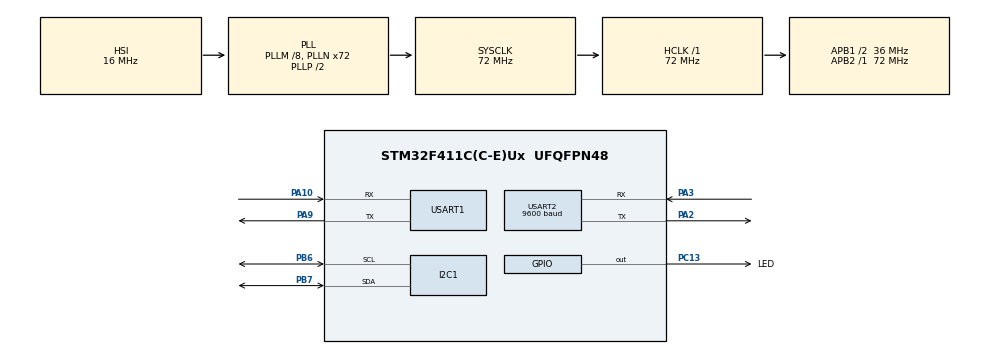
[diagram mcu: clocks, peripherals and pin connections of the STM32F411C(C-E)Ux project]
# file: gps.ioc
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Mcu.Family=STM32F4
Mcu.Name=STM32F411C(C-E)Ux
Mcu.Package=UFQFPN48
NVIC.PriorityGroup=NVIC_PRIORITYGROUP_4
NVIC.USART2_IRQn=true\:0\:0\:false\:false\:true\:true\:true
PA10.Mode=Asynchronous
PA10.Signal=USART1_RX
PA13.Mode=Serial_Wire
PA13.Signal=SYS_JTMS-SWDIO
PA14.Mode=Serial_Wire
PA14.Signal=SYS_JTCK-SWCLK
PA2.Mode=Asynchronous
PA2.Signal=USART2_TX
PA3.Mode=Asynchronous
PA3.Signal=USART2_RX
PA9.Mode=Asynchronous
PA9.Signal=USART1_TX
PB6.Mode=I2C
PB6.Signal=I2C1_SCL
PB7.Mode=I2C
PB7.Signal=I2C1_SDA
PC13-ANTI_TAMP.GPIO_Label=LED
PC13-ANTI_TAMP.Signal=GPIO_Output
PH0\ -\ OSC_IN.Mode=HSE-External-Oscillator
PH0\ -\ OSC_IN.Signal=RCC_OSC_IN
PH1\ -\ OSC_OUT.Mode=HSE-External-Oscillator
PH1\ -\ OSC_OUT.Signal=RCC_OSC_OUT
ProjectManager.HeapSize=0x200
ProjectManager.StackSize=0x400
ProjectManager.TargetToolchain=STM32CubeIDE
RCC.48MHZClocksFreq_Value=36000000
RCC.AHBFreq_Value=72000000
RCC.APB1CLKDivider=RCC_HCLK_DIV2
RCC.APB1Freq_Value=36000000
RCC.APB1TimFreq_Value=72000000
RCC.APB2Freq_Value=72000000
RCC.APB2TimFreq_Value=72000000
RCC.CortexFreq_Value=72000000
RCC.HCLKFreq_Value=72000000
RCC.HSE_VALUE=25000000
RCC.HSI_VALUE=16000000
RCC.LSE_VALUE=32768
RCC.PLLM=8
RCC.PLLN=72
RCC.SYSCLKFreq_VALUE=72000000
RCC.SYSCLKSource=RCC_SYSCLKSOURCE_PLLCLK
RCC.VCOOutputFreq_Value=144000000
USART1.VirtualMode=VM_ASYNC
USART2.BaudRate=9600
USART2.VirtualMode=VM_ASYNC
board=custom

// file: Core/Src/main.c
/* USER CODE BEGIN Header */
/**
  ******************************************************************************
  * @file           : main.c
  * @brief          : Main program body
  ******************************************************************************
  * @attention
  *
  * Copyright (c) 2021 STMicroelectronics.
  * All rights reserved.
  *
  * This software is licensed under terms that can be found in the LICENSE file
  * in the root directory of this software component.
  * If no LICENSE file comes with this software, it is provided AS-IS.
  *
  ******************************************************************************
  */
/* USER CODE END Header */
#include "main.h"

/* USER CODE BEGIN Includes */
#include <stdio.h>
#include "gps.h"
/* USER CODE END Includes */

I2C_HandleTypeDef hi2c1;

UART_HandleTypeDef huart1;
UART_HandleTypeDef huart2;

/* USER CODE BEGIN PV */
uint8_t Message[64];
uint8_t MessageLength;
/* USER CODE END PV */

void SystemClock_Config(void);
static void MX_GPIO_Init(void);
static void MX_USART1_UART_Init(void);
static void MX_I2C1_Init(void);
static void MX_USART2_UART_Init(void);

int main(void)
{

  /* MCU Configuration--------------------------------------------------------*/

  /* Reset of all peripherals, Initializes the Flash interface and the Systick. */
  HAL_Init();

  /* Configure the system clock */
  SystemClock_Config();

  /* Initialize all configured peripherals */
  MX_GPIO_Init();
  MX_USART1_UART_Init();
  MX_I2C1_Init();
  MX_USART2_UART_Init();
  /* USER CODE BEGIN 2 */
  NEO6_Init(&GpsState, &huart2);

  uint32_t Timer = HAL_GetTick();
  /* USER CODE END 2 */

  /* Infinite loop */
  while (1)
  {
	  NEO6_Task(&GpsState);

	  	  if((HAL_GetTick() - Timer) > 1000)
	  	  {
	  		  MessageLength = sprintf((char*)Message, " \n\r  "); // Clear terminal and home cursor
	  		  HAL_UART_Transmit(&huart1, Message, MessageLength, 1000);

	  		  if(NEO6_IsFix(&GpsState) && NEO6_FixMode(&GpsState))
	  		  {
	  			  MessageLength = sprintf((char*)Message, "UTC Time: %02d:%02d:%02d\n\r", GpsState.Hour, GpsState.Minute, GpsState.Second);
	  			  HAL_UART_Transmit(&huart1, Message, MessageLength, 1000);

	  			  MessageLength = sprintf((char*)Message, "Date: %02d.%02d.20%02d\n\r", GpsState.Day, GpsState.Month, GpsState.Year);
	  			  HAL_UART_Transmit(&huart1, Message, MessageLength, 1000);

	  			  MessageLength = sprintf((char*)Message, "Latitude: %.2f %c\n\r", GpsState.Latitude, GpsState.LatitudeDirection);
	  			  HAL_UART_Transmit(&huart1, Message, MessageLength, 1000);

	  			  MessageLength = sprintf((char*)Message, "Longitude: %.2f %c\n\r", GpsState.Longitude, GpsState.LongitudeDirection);
	  			  HAL_UART_Transmit(&huart1, Message, MessageLength, 1000);

	  			  MessageLength = sprintf((char*)Message, "Altitude: %.2f m above sea level\n\r", GpsState.Altitude);
	  			  HAL_UART_Transmit(&huart1, Message, MessageLength, 1000);

	  			  /*MessageLength = sprintf((char*)Message, "PositionValid: ");
	  			  HAL_UART_Transmit(&huart1, Message, MessageLength, 1000);
	  			  //MessageLength = sprintf((char*)Message, GpsState.PositionValid);
	  				  			  HAL_UART_Transmit(&huart1, GpsState.PositionValid, 1, 1000);
	  				  			MessageLength = sprintf((char*)Message, "\n\r ");
	  				  				  			  HAL_UART_Transmit(&huart1, Message, MessageLength, 1000);*/

	  			  MessageLength = sprintf((char*)Message, "Speed: %.2f knots, %f km/h\n\r", GpsState.SpeedKnots, GpsState.SpeedKilometers);
	  			  HAL_UART_Transmit(&huart1, Message, MessageLength, 1000);
	  			  MessageLength = sprintf((char*)Message, "Course: %.2f degrees\n\r", GpsState.Course);
	  			  HAL_UART_Transmit(&huart1, Message, MessageLength, 1000);
	  			  MessageLength = sprintf((char*)Message, "MagneticDeclination: %.2f degrees\n\r", GpsState.MagneticDeclination);
	  			  HAL_UART_Transmit(&huart1, Message, MessageLength, 1000);

	  			  MessageLength = sprintf((char*)Message, "Satelites: %d\n\r", GpsState.SatelitesNumber);
	  			  HAL_UART_Transmit(&huart1, Message, MessageLength, 1000);

	  			  MessageLength = sprintf((char*)Message, "Dilution of precision: %.2f\n\r", GpsState.Dop);
	  			  HAL_UART_Transmit(&huart1, Message, MessageLength, 1000);

	  			  MessageLength = sprintf((char*)Message, "Horizontal dilution of precision: %.2f\n\r", GpsState.Hdop);
	  			  HAL_UART_Transmit(&huart1, Message, MessageLength, 1000);

	  			  MessageLength = sprintf((char*)Message, "Vertical dilution of precision: %.2f\n\r", GpsState.Vdop);
	  			  HAL_UART_Transmit(&huart1, Message, MessageLength, 1000);
	  		  }
	  		  else
	  		  {
	  			  MessageLength = sprintf((char*)Message, "No Fix\n\r");
	  			  HAL_UART_Transmit(&huart1, Message, MessageLength, 1000);
	  		  }

	  		  Timer = HAL_GetTick();
  }
}
}

void SystemClock_Config(void)
{
  RCC_OscInitTypeDef RCC_OscInitStruct = {0};
  RCC_ClkInitTypeDef RCC_ClkInitStruct = {0};

  /** Configure the main internal regulator output voltage
  */
  __HAL_RCC_PWR_CLK_ENABLE();
  __HAL_PWR_VOLTAGESCALING_CONFIG(PWR_REGULATOR_VOLTAGE_SCALE1);
  /** Initializes the RCC Oscillators according to the specified parameters
  * in the RCC_OscInitTypeDef structure.
  */
  RCC_OscInitStruct.OscillatorType = RCC_OSCILLATORTYPE_HSI;
  RCC_OscInitStruct.HSIState = RCC_HSI_ON;
  RCC_OscInitStruct.HSICalibrationValue = RCC_HSICALIBRATION_DEFAULT;
  RCC_OscInitStruct.PLL.PLLState = RCC_PLL_ON;
  RCC_OscInitStruct.PLL.PLLSource = RCC_PLLSOURCE_HSI;
  RCC_OscInitStruct.PLL.PLLM = 8;
  RCC_OscInitStruct.PLL.PLLN = 72;
  RCC_OscInitStruct.PLL.PLLP = RCC_PLLP_DIV2;
  RCC_OscInitStruct.PLL.PLLQ = 4;
  if (HAL_RCC_OscConfig(&RCC_OscInitStruct) != HAL_OK)
  {
    Error_Handler();
  }
  /** Initializes the CPU, AHB and APB buses clocks
  */
  RCC_ClkInitStruct.ClockType = RCC_CLOCKTYPE_HCLK|RCC_CLOCKTYPE_SYSCLK
                              |RCC_CLOCKTYPE_PCLK1|RCC_CLOCKTYPE_PCLK2;
  RCC_ClkInitStruct.SYSCLKSource = RCC_SYSCLKSOURCE_PLLCLK;
  RCC_ClkInitStruct.AHBCLKDivider = RCC_SYSCLK_DIV1;
  RCC_ClkInitStruct.APB1CLKDivider = RCC_HCLK_DIV2;
  RCC_ClkInitStruct.APB2CLKDivider = RCC_HCLK_DIV1;

  if (HAL_RCC_ClockConfig(&RCC_ClkInitStruct, FLASH_LATENCY_2) != HAL_OK)
  {
    Error_Handler();
  }
}

static void MX_I2C1_Init(void)
{

  hi2c1.Instance = I2C1;
  hi2c1.Init.ClockSpeed = 100000;
  hi2c1.Init.DutyCycle = I2C_DUTYCYCLE_2;
  hi2c1.Init.OwnAddress1 = 0;
  hi2c1.Init.AddressingMode = I2C_ADDRESSINGMODE_7BIT;
  hi2c1.Init.DualAddressMode = I2C_DUALADDRESS_DISABLE;
  hi2c1.Init.OwnAddress2 = 0;
  hi2c1.Init.GeneralCallMode = I2C_GENERALCALL_DISABLE;
  hi2c1.Init.NoStretchMode = I2C_NOSTRETCH_DISABLE;
  if (HAL_I2C_Init(&hi2c1) != HAL_OK)
  {
    Error_Handler();
  }

}

static void MX_USART1_UART_Init(void)
{

  huart1.Instance = USART1;
  huart1.Init.BaudRate = 115200;
  huart1.Init.WordLength = UART_WORDLENGTH_8B;
  huart1.Init.StopBits = UART_STOPBITS_1;
  huart1.Init.Parity = UART_PARITY_NONE;
  huart1.Init.Mode = UART_MODE_TX_RX;
  huart1.Init.HwFlowCtl = UART_HWCONTROL_NONE;
  huart1.Init.OverSampling = UART_OVERSAMPLING_16;
  if (HAL_UART_Init(&huart1) != HAL_OK)
  {
    Error_Handler();
  }

}

static void MX_USART2_UART_Init(void)
{

  huart2.Instance = USART2;
  huart2.Init.BaudRate = 9600;
  huart2.Init.WordLength = UART_WORDLENGTH_8B;
  huart2.Init.StopBits = UART_STOPBITS_1;
  huart2.Init.Parity = UART_PARITY_NONE;
  huart2.Init.Mode = UART_MODE_TX_RX;
  huart2.Init.HwFlowCtl = UART_HWCONTROL_NONE;
  huart2.Init.OverSampling = UART_OVERSAMPLING_16;
  if (HAL_UART_Init(&huart2) != HAL_OK)
  {
    Error_Handler();
  }

}

static void MX_GPIO_Init(void)
{
  GPIO_InitTypeDef GPIO_InitStruct = {0};

  /* GPIO Ports Clock Enable */
  __HAL_RCC_GPIOC_CLK_ENABLE();
  __HAL_RCC_GPIOH_CLK_ENABLE();
  __HAL_RCC_GPIOA_CLK_ENABLE();
  __HAL_RCC_GPIOB_CLK_ENABLE();

  /*Configure GPIO pin Output Level */
  HAL_GPIO_WritePin(LED_GPIO_Port, LED_Pin, GPIO_PIN_RESET);

  /*Configure GPIO pin : LED_Pin */
  GPIO_InitStruct.Pin = LED_Pin;
  GPIO_InitStruct.Mode = GPIO_MODE_OUTPUT_PP;
  GPIO_InitStruct.Pull = GPIO_NOPULL;
  GPIO_InitStruct.Speed = GPIO_SPEED_FREQ_LOW;
  HAL_GPIO_Init(LED_GPIO_Port, &GPIO_InitStruct);

}

/* USER CODE BEGIN 4 */
void HAL_UART_RxCpltCallback(UART_HandleTypeDef *huart)
{
	if(huart == GpsState.neo6_huart)
	{
		NEO6_ReceiveUartChar(&GpsState);
	}
}
/* USER CODE END 4 */

void Error_Handler(void)
{
  __disable_irq();
  while (1)
  {
  }
}
